AUTOSAR XML (schema 4-0-3)
package /ComponentTypes
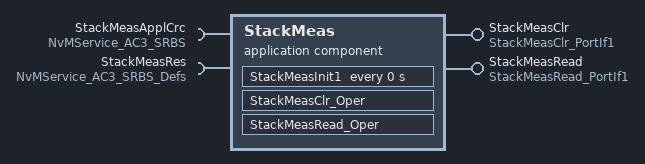
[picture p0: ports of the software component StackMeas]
  application sw component type StackMeas
    provide port StackMeasClr: server-com-spec{operation=Oper, queue-length=1}, provided-interface=StackMeasClr_PortIf1
    provide port StackMeasRead: server-com-spec{operation=Operation, queue-length=1}, provided-interface=StackMeasRead_PortIf1
    require port StackMeasApplCrc: required-com-specs=[EraseBlock, GetErrorStatus, InvalidateNvBlock, ReadBlock, SetRamBlockStatus, WriteBlock], required-interface=NvMService_AC3_SRBS
    require port StackMeasRes: required-com-specs=[EraseBlock, GetErrorStatus, InvalidateNvBlock, ReadBlock, RestoreBlockDefaults, SetRamBlockStatus, WriteBlock], required-interface=NvMService_AC3_SRBS_Defs
    behavior StackMeas_InternalBehavior
      ar-typed-per-instance-memorys:
        data StackMeasApplCrc: sw-calibration-access=READ-ONLY, type=uint32
        data StackMeasRes: sw-calibration-access=READ-ONLY, type=Ary1D_u8_48
      operation invoked event OIT_StackMeasClr_PortIf1_Oper_StackMeasClr_PortIf1_Oper: start-on-event=StackMeasClr_Oper, operation=StackMeasClr.Oper
      timing event StackMeas_InitEvent: start-on-event=StackMeasInit1, period=0
      operation invoked event OIT_StackMeasRead_PortIf1_Operation_StackMeasRead_PortIf1_Operation: start-on-event=StackMeasRead_Oper, operation=StackMeasRead.Operation
      port-api-options:
        enable-take-address=false, indirect-api=false, port=StackMeasApplCrc
        enable-take-address=false, indirect-api=false, port=StackMeasClr
        enable-take-address=false, indirect-api=false, port=StackMeasRead
        enable-take-address=false, indirect-api=false, port=StackMeasRes
      runnable StackMeasClr_Oper
        sync call SC_StackMeasRes_RestoreBlockDefaults: operation=StackMeasRes.RestoreBlockDefaults, timeout=0
      runnable StackMeasInit1
        4 x sync call, all with timeout=0:
          SC_StackMeasCntr_GetErrorStatus: operation=StackMeasApplCrc.GetErrorStatus
          SC_StackMeasCntr_SetRamBlockStatus: operation=StackMeasApplCrc.SetRamBlockStatus
          SC_StackMeasRes_GetErrorStatus: operation=StackMeasRes.GetErrorStatus
          SC_StackMeasRes_SetRamBlockStatus: operation=StackMeasRes.SetRamBlockStatus
      runnable StackMeasRead_Oper
      swc service dependency NvMStackMeasApplCrc: assigned-datas=role-based-data-assignment={role=ramBlock, used-data-element=StackMeasApplCrc}, assigned-ports=role-based-port-assignment={port-prototype=StackMeasApplCrc, role=NvMService_AC3_SRBS}
        service-needs:
          nv block needs NvMStackMeasApplCrc: n-data-sets=0, readonly=false, reliability=ERROR-DETECTION, resistant-to-changed-sw=true, restore-at-start=true, store-at-shutdown=true, write-only-once=false, writing-frequency=0, writing-priority=LOW
      swc service dependency NvMStackMeasRes: assigned-ports=role-based-port-assignment={port-prototype=StackMeasRes, role=NvMService_AC3_SRBS}
        assigned-datas:
          role=ramBlock, used-data-element=StackMeasRes
          role=defaultValue, used-parameter-element=StackMeasResDft
        service-needs:
          nv block needs NvMStackMeasRes: n-data-sets=0, readonly=false, reliability=ERROR-DETECTION, resistant-to-changed-sw=true, restore-at-start=true, store-at-shutdown=true, write-only-once=false, writing-frequency=0, writing-priority=LOW
      shared-parameters:
        parameter data prototype StackMeasResDft: sw-calibration-access=READ-WRITE, type=Ary1D_u8_48, init-value=48 x 0
  swc implementation StackMeas_Implementation: behavior=StackMeas_InternalBehavior
    code-descriptors:
      code Default: artifact-descriptors=autosar-engineering-object={short-label=Default, category=SWSRC}
